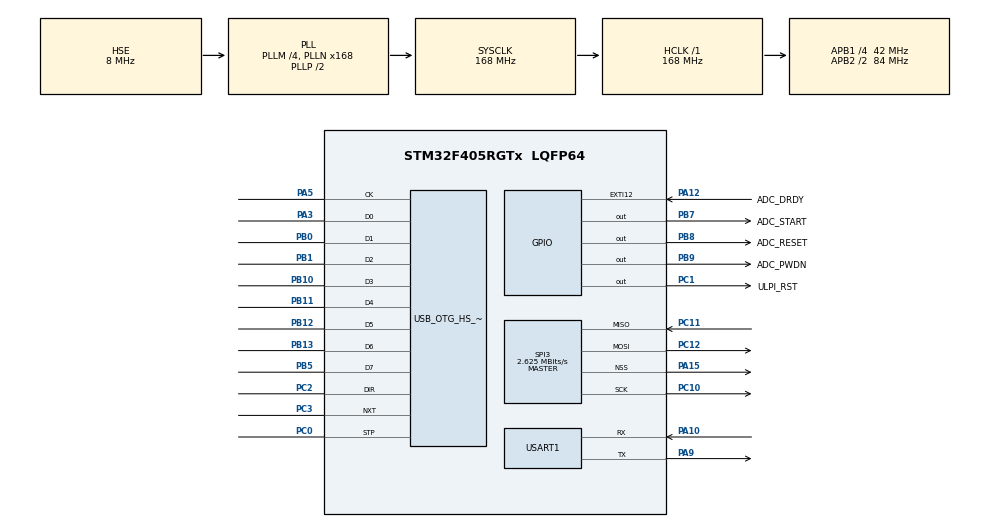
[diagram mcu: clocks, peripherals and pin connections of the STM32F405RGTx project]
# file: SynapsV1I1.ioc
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Dma.Request0=SPI3_RX
Dma.Request1=SPI3_TX
Dma.SPI3_RX.0.Direction=DMA_PERIPH_TO_MEMORY
Dma.SPI3_RX.0.FIFOMode=DMA_FIFOMODE_DISABLE
Dma.SPI3_RX.0.Instance=DMA1_Stream0
Dma.SPI3_RX.0.MemDataAlignment=DMA_MDATAALIGN_BYTE
Dma.SPI3_RX.0.MemInc=DMA_MINC_ENABLE
Dma.SPI3_RX.0.Mode=DMA_NORMAL
Dma.SPI3_RX.0.PeriphDataAlignment=DMA_PDATAALIGN_BYTE
Dma.SPI3_RX.0.PeriphInc=DMA_PINC_DISABLE
Dma.SPI3_RX.0.Priority=DMA_PRIORITY_HIGH
Dma.SPI3_TX.1.Direction=DMA_MEMORY_TO_PERIPH
Dma.SPI3_TX.1.FIFOMode=DMA_FIFOMODE_DISABLE
Dma.SPI3_TX.1.Instance=DMA1_Stream5
Dma.SPI3_TX.1.MemDataAlignment=DMA_MDATAALIGN_BYTE
Dma.SPI3_TX.1.MemInc=DMA_MINC_ENABLE
Dma.SPI3_TX.1.Mode=DMA_NORMAL
Dma.SPI3_TX.1.PeriphDataAlignment=DMA_PDATAALIGN_BYTE
Dma.SPI3_TX.1.PeriphInc=DMA_PINC_DISABLE
Dma.SPI3_TX.1.Priority=DMA_PRIORITY_HIGH
FREERTOS.BinarySemaphores01=adcDataReadySemathore,Dynamic,NULL
FREERTOS.INCLUDE_pcTaskGetTaskName=0
FREERTOS.INCLUDE_uxTaskPriorityGet=0
FREERTOS.INCLUDE_vTaskDelayUntil=1
FREERTOS.INCLUDE_vTaskDelete=0
FREERTOS.INCLUDE_vTaskPrioritySet=0
FREERTOS.Queues01=USB_Tx_Queue,8192,uint8_t,0,Dynamic,NULL,NULL;USB_Rx_Queue,512,uint8_t,0,Dynamic,NULL,NULL;SerialTxQueue,8192,uint8_t,0,Dynamic,NULL,NULL;SerialRxQueue,256,uint8_t,0,Dynamic,NULL,NULL
FREERTOS.Tasks01=defaultTask,0,128,StartDefaultTask,Default,NULL,Dynamic,NULL,NULL;USB,0,1024,usbTaskWorker,As external,NULL,Dynamic,NULL,NULL;OpenBCI,0,1024,OpenBCITaskWorker,As external,NULL,Dynamic,NULL,NULL;CmdProc,0,1024,OpenBCICommandTaskWorker,As external,NULL,Dynamic,NULL,NULL
FREERTOS.configTOTAL_HEAP_SIZE=32768
Mcu.Family=STM32F4
Mcu.Name=STM32F405RGTx
Mcu.Package=LQFP64
NVIC.DMA1_Stream0_IRQn=true\:5\:0\:false\:false\:true\:true\:false
NVIC.DMA1_Stream5_IRQn=true\:5\:0\:false\:false\:true\:true\:false
NVIC.EXTI15_10_IRQn=true\:5\:0\:false\:false\:true\:true\:true
NVIC.OTG_HS_IRQn=true\:5\:0\:false\:false\:true\:true\:false
NVIC.PriorityGroup=NVIC_PRIORITYGROUP_4
NVIC.TIM8_TRG_COM_TIM14_IRQn=true\:0\:0\:false\:false\:true\:false\:false
NVIC.TimeBase=TIM8_TRG_COM_TIM14_IRQn
NVIC.TimeBaseIP=TIM14
NVIC.USART1_IRQn=true\:5\:0\:false\:false\:true\:true\:true
PA10.Mode=Asynchronous
PA10.Signal=USART1_RX
PA12.GPIO_Label=ADC_DRDY
PA12.GPIO_ModeDefaultEXTI=GPIO_MODE_IT_FALLING
PA12.GPIO_PuPd=GPIO_PULLUP
PA12.Signal=GPXTI12
PA13.Mode=Serial_Wire
PA13.Signal=SYS_JTMS-SWDIO
PA14.Mode=Serial_Wire
PA14.Signal=SYS_JTCK-SWCLK
PA15.Mode=NSS_Signal_Hard_Output
PA15.Signal=SPI3_NSS
PA3.Mode=Device_HS
PA3.Signal=USB_OTG_HS_ULPI_D0
PA5.Mode=Device_HS
PA5.Signal=USB_OTG_HS_ULPI_CK
PA9.Mode=Asynchronous
PA9.Signal=USART1_TX
PB0.Mode=Device_HS
PB0.Signal=USB_OTG_HS_ULPI_D1
PB1.Mode=Device_HS
PB1.Signal=USB_OTG_HS_ULPI_D2
PB10.Mode=Device_HS
PB10.Signal=USB_OTG_HS_ULPI_D3
PB11.Mode=Device_HS
PB11.Signal=USB_OTG_HS_ULPI_D4
PB12.Mode=Device_HS
PB12.Signal=USB_OTG_HS_ULPI_D5
PB13.Mode=Device_HS
PB13.Signal=USB_OTG_HS_ULPI_D6
PB5.Mode=Device_HS
PB5.Signal=USB_OTG_HS_ULPI_D7
PB7.GPIO_Label=ADC_START
PB7.Signal=GPIO_Output
PB8.GPIO_Label=ADC_RESET
PB8.GPIO_PuPd=GPIO_NOPULL
PB8.PinState=GPIO_PIN_SET
PB8.Signal=GPIO_Output
PB9.GPIO_Label=ADC_PWDN
PB9.PinState=GPIO_PIN_SET
PB9.Signal=GPIO_Output
PC0.Mode=Device_HS
PC0.Signal=USB_OTG_HS_ULPI_STP
PC1.GPIO_Label=ULPI_RST
PC1.Signal=GPIO_Output
PC10.Mode=Full_Duplex_Master
PC10.Signal=SPI3_SCK
PC11.Mode=Full_Duplex_Master
PC11.Signal=SPI3_MISO
PC12.Mode=Full_Duplex_Master
PC12.Signal=SPI3_MOSI
PC2.Mode=Device_HS
PC2.Signal=USB_OTG_HS_ULPI_DIR
PC3.Mode=Device_HS
PC3.Signal=USB_OTG_HS_ULPI_NXT
PH0-OSC_IN.Mode=HSE-External-Oscillator
PH0-OSC_IN.Signal=RCC_OSC_IN
PH1-OSC_OUT.Mode=HSE-External-Oscillator
PH1-OSC_OUT.Signal=RCC_OSC_OUT
ProjectManager.HeapSize=0x200
ProjectManager.StackSize=0x400
ProjectManager.TargetToolchain=SW4STM32
RCC.48MHZClocksFreq_Value=84000000
RCC.AHBFreq_Value=168000000
RCC.APB1CLKDivider=RCC_HCLK_DIV4
RCC.APB1Freq_Value=42000000
RCC.APB1TimFreq_Value=84000000
RCC.APB2CLKDivider=RCC_HCLK_DIV2
RCC.APB2Freq_Value=84000000
RCC.APB2TimFreq_Value=168000000
RCC.CortexFreq_Value=168000000
RCC.HCLKFreq_Value=168000000
RCC.HSE_VALUE=8000000
RCC.HSI_VALUE=16000000
RCC.LSE_VALUE=32768
RCC.PLLM=4
RCC.PLLN=168
RCC.PLLSourceVirtual=RCC_PLLSOURCE_HSE
RCC.SYSCLKFreq_VALUE=168000000
RCC.SYSCLKSource=RCC_SYSCLKSOURCE_PLLCLK
RCC.VCOOutputFreq_Value=336000000
SPI3.BaudRatePrescaler=SPI_BAUDRATEPRESCALER_16
SPI3.CLKPhase=SPI_PHASE_2EDGE
SPI3.CLKPolarity=SPI_POLARITY_LOW
SPI3.CalculateBaudRate=2.625 MBits/s
SPI3.Direction=SPI_DIRECTION_2LINES
SPI3.Mode=SPI_MODE_MASTER
SPI3.VirtualNSS=VM_NSSHARD
SPI3.VirtualType=VM_MASTER
USART1.VirtualMode=VM_ASYNC
USB_DEVICE.CLASS_NAME_HS=CDC
USB_DEVICE.VirtualMode-CDC_HS=Cdc
USB_DEVICE.VirtualModeHS=Cdc_HS
USB_OTG_HS.VirtualMode-Device_HS=Device_HS
VP_CRC_VS_CRC.Mode=CRC_Activate
VP_FREERTOS_VS_ENABLE.Mode=Enabled
VP_IWDG_VS_IWDG.Mode=IWDG_Activate
VP_SYS_VS_tim14.Mode=TIM14
VP_USB_DEVICE_VS_USB_DEVICE_CDC_HS.Mode=CDC_HS
board=SynapsV1I1

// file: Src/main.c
/* USER CODE BEGIN Header */
/**
  ******************************************************************************
  * @file           : main.c
  * @brief          : Main program body
  ******************************************************************************
  * This notice applies to any and all portions of this file
  * that are not between comment pairs USER CODE BEGIN and
  * USER CODE END. Other portions of this file, whether
  * inserted by the user or by software development tools
  * are owned by their respective copyright owners.
  *
  * Copyright (c) 2018 STMicroelectronics International N.V.
  * All rights reserved.
  *
  * Redistribution and use in source and binary forms, with or without
  * modification, are permitted, provided that the following conditions are met:
  *
  * 1. Redistribution of source code must retain the above copyright notice,
  *    this list of conditions and the following disclaimer.
  * 2. Redistributions in binary form must reproduce the above copyright notice,
  *    this list of conditions and the following disclaimer in the documentation
  *    and/or other materials provided with the distribution.
  * 3. Neither the name of STMicroelectronics nor the names of other
  *    contributors to this software may be used to endorse or promote products
  *    derived from this software without specific written permission.
  * 4. This software, including modifications and/or derivative works of this
  *    software, must execute solely and exclusively on microcontroller or
  *    microprocessor devices manufactured by or for STMicroelectronics.
  * 5. Redistribution and use of this software other than as permitted under
  *    this license is void and will automatically terminate your rights under
  *    this license.
  *
  * THIS SOFTWARE IS PROVIDED BY STMICROELECTRONICS AND CONTRIBUTORS "AS IS"
  * AND ANY EXPRESS, IMPLIED OR STATUTORY WARRANTIES, INCLUDING, BUT NOT
  * LIMITED TO, THE IMPLIED WARRANTIES OF MERCHANTABILITY, FITNESS FOR A
  * PARTICULAR PURPOSE AND NON-INFRINGEMENT OF THIRD PARTY INTELLECTUAL PROPERTY
  * RIGHTS ARE DISCLAIMED TO THE FULLEST EXTENT PERMITTED BY LAW. IN NO EVENT
  * SHALL STMICROELECTRONICS OR CONTRIBUTORS BE LIABLE FOR ANY DIRECT, INDIRECT,
  * INCIDENTAL, SPECIAL, EXEMPLARY, OR CONSEQUENTIAL DAMAGES (INCLUDING, BUT NOT
  * LIMITED TO, PROCUREMENT OF SUBSTITUTE GOODS OR SERVICES; LOSS OF USE, DATA,
  * OR PROFITS; OR BUSINESS INTERRUPTION) HOWEVER CAUSED AND ON ANY THEORY OF
  * LIABILITY, WHETHER IN CONTRACT, STRICT LIABILITY, OR TORT (INCLUDING
  * NEGLIGENCE OR OTHERWISE) ARISING IN ANY WAY OUT OF THE USE OF THIS SOFTWARE,
  * EVEN IF ADVISED OF THE POSSIBILITY OF SUCH DAMAGE.
  *
  ******************************************************************************
  */
/* USER CODE END Header */

#include "main.h"
#include "cmsis_os.h"
#include "crc.h"
#include "dma.h"
#include "iwdg.h"
#include "spi.h"
#include "usart.h"
#include "usb_device.h"
#include "gpio.h"

/* USER CODE BEGIN PV */
/* Private variables ---------------------------------------------------------*/

/* USER CODE END PV */

void SystemClock_Config(void);
void MX_FREERTOS_Init(void);
/* USER CODE BEGIN PFP */
/* Private function prototypes -----------------------------------------------*/

/* USER CODE END PFP */

int main(void)
{

  /* MCU Configuration--------------------------------------------------------*/

  /* Reset of all peripherals, Initializes the Flash interface and the Systick. */
  HAL_Init();

  /* Configure the system clock */
  SystemClock_Config();

  /* Initialize all configured peripherals */
  MX_GPIO_Init();
  MX_DMA_Init();
  MX_CRC_Init();
  MX_IWDG_Init();
  MX_SPI3_Init();
  MX_USART1_UART_Init();

  /* Call init function for freertos objects (in freertos.c) */
  MX_FREERTOS_Init();

  /* Start scheduler */
  osKernelStart();

  /* We should never get here as control is now taken by the scheduler */

  /* Infinite loop */
  while (1)
  {

  }
}

void SystemClock_Config(void)
{
  RCC_OscInitTypeDef RCC_OscInitStruct = {0};
  RCC_ClkInitTypeDef RCC_ClkInitStruct = {0};

  /**Configure the main internal regulator output voltage
  */
  __HAL_RCC_PWR_CLK_ENABLE();
  __HAL_PWR_VOLTAGESCALING_CONFIG(PWR_REGULATOR_VOLTAGE_SCALE1);
  /**Initializes the CPU, AHB and APB busses clocks
  */
  RCC_OscInitStruct.OscillatorType = RCC_OSCILLATORTYPE_LSI|RCC_OSCILLATORTYPE_HSE;
  RCC_OscInitStruct.HSEState = RCC_HSE_ON;
  RCC_OscInitStruct.LSIState = RCC_LSI_ON;
  RCC_OscInitStruct.PLL.PLLState = RCC_PLL_ON;
  RCC_OscInitStruct.PLL.PLLSource = RCC_PLLSOURCE_HSE;
  RCC_OscInitStruct.PLL.PLLM = 4;
  RCC_OscInitStruct.PLL.PLLN = 168;
  RCC_OscInitStruct.PLL.PLLP = RCC_PLLP_DIV2;
  RCC_OscInitStruct.PLL.PLLQ = 4;
  if (HAL_RCC_OscConfig(&RCC_OscInitStruct) != HAL_OK)
  {
    Error_Handler();
  }
  /**Initializes the CPU, AHB and APB busses clocks
  */
  RCC_ClkInitStruct.ClockType = RCC_CLOCKTYPE_HCLK|RCC_CLOCKTYPE_SYSCLK
                              |RCC_CLOCKTYPE_PCLK1|RCC_CLOCKTYPE_PCLK2;
  RCC_ClkInitStruct.SYSCLKSource = RCC_SYSCLKSOURCE_PLLCLK;
  RCC_ClkInitStruct.AHBCLKDivider = RCC_SYSCLK_DIV1;
  RCC_ClkInitStruct.APB1CLKDivider = RCC_HCLK_DIV4;
  RCC_ClkInitStruct.APB2CLKDivider = RCC_HCLK_DIV2;

  if (HAL_RCC_ClockConfig(&RCC_ClkInitStruct, FLASH_LATENCY_5) != HAL_OK)
  {
    Error_Handler();
  }
}

void HAL_TIM_PeriodElapsedCallback(TIM_HandleTypeDef *htim)
{
  if (htim->Instance == TIM14) {
    HAL_IncTick();
  }
}

void Error_Handler(void)
{
  while(1)
  {
  }
}

/************************ (C) COPYRIGHT STMicroelectronics *****END OF FILE****/

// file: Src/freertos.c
/* USER CODE BEGIN Header */
/**
  ******************************************************************************
  * File Name          : freertos.c
  * Description        : Code for freertos applications
  ******************************************************************************
  * This notice applies to any and all portions of this file
  * that are not between comment pairs USER CODE BEGIN and
  * USER CODE END. Other portions of this file, whether
  * inserted by the user or by software development tools
  * are owned by their respective copyright owners.
  *
  * Copyright (c) 2018 STMicroelectronics International N.V.
  * All rights reserved.
  *
  * Redistribution and use in source and binary forms, with or without
  * modification, are permitted, provided that the following conditions are met:
  *
  * 1. Redistribution of source code must retain the above copyright notice,
  *    this list of conditions and the following disclaimer.
  * 2. Redistributions in binary form must reproduce the above copyright notice,
  *    this list of conditions and the following disclaimer in the documentation
  *    and/or other materials provided with the distribution.
  * 3. Neither the name of STMicroelectronics nor the names of other
  *    contributors to this software may be used to endorse or promote products
  *    derived from this software without specific written permission.
  * 4. This software, including modifications and/or derivative works of this
  *    software, must execute solely and exclusively on microcontroller or
  *    microprocessor devices manufactured by or for STMicroelectronics.
  * 5. Redistribution and use of this software other than as permitted under
  *    this license is void and will automatically terminate your rights under
  *    this license.
  *
  * THIS SOFTWARE IS PROVIDED BY STMICROELECTRONICS AND CONTRIBUTORS "AS IS"
  * AND ANY EXPRESS, IMPLIED OR STATUTORY WARRANTIES, INCLUDING, BUT NOT
  * LIMITED TO, THE IMPLIED WARRANTIES OF MERCHANTABILITY, FITNESS FOR A
  * PARTICULAR PURPOSE AND NON-INFRINGEMENT OF THIRD PARTY INTELLECTUAL PROPERTY
  * RIGHTS ARE DISCLAIMED TO THE FULLEST EXTENT PERMITTED BY LAW. IN NO EVENT
  * SHALL STMICROELECTRONICS OR CONTRIBUTORS BE LIABLE FOR ANY DIRECT, INDIRECT,
  * INCIDENTAL, SPECIAL, EXEMPLARY, OR CONSEQUENTIAL DAMAGES (INCLUDING, BUT NOT
  * LIMITED TO, PROCUREMENT OF SUBSTITUTE GOODS OR SERVICES; LOSS OF USE, DATA,
  * OR PROFITS; OR BUSINESS INTERRUPTION) HOWEVER CAUSED AND ON ANY THEORY OF
  * LIABILITY, WHETHER IN CONTRACT, STRICT LIABILITY, OR TORT (INCLUDING
  * NEGLIGENCE OR OTHERWISE) ARISING IN ANY WAY OUT OF THE USE OF THIS SOFTWARE,
  * EVEN IF ADVISED OF THE POSSIBILITY OF SUCH DAMAGE.
  *
  ******************************************************************************
  */
/* USER CODE END Header */

#include "FreeRTOS.h"
#include "task.h"
#include "main.h"
#include "cmsis_os.h"

/* USER CODE BEGIN Includes */
#include "iwdg.h"

/* USER CODE END Includes */

osThreadId defaultTaskHandle;
osThreadId USBHandle;
osThreadId OpenBCIHandle;
osThreadId CmdProcHandle;
osMessageQId USB_Tx_QueueHandle;
osMessageQId USB_Rx_QueueHandle;
osMessageQId SerialTxQueueHandle;
osMessageQId SerialRxQueueHandle;
osSemaphoreId adcDataReadySemathoreHandle;

void StartDefaultTask(void const * argument);
extern void usbTaskWorker(void const * argument);
extern void OpenBCITaskWorker(void const * argument);
extern void OpenBCICommandTaskWorker(void const * argument);

extern void MX_USB_DEVICE_Init(void);
void MX_FREERTOS_Init(void); /* (MISRA C 2004 rule 8.1) */

void MX_FREERTOS_Init(void) {

  /* Create the semaphores(s) */
  /* definition and creation of adcDataReadySemathore */
  osSemaphoreDef(adcDataReadySemathore);
  adcDataReadySemathoreHandle = osSemaphoreCreate(osSemaphore(adcDataReadySemathore), 1);

  /* Create the thread(s) */
  /* definition and creation of defaultTask */
  osThreadDef(defaultTask, StartDefaultTask, osPriorityNormal, 0, 128);
  defaultTaskHandle = osThreadCreate(osThread(defaultTask), NULL);

  /* definition and creation of USB */
  osThreadDef(USB, usbTaskWorker, osPriorityNormal, 0, 1024);
  USBHandle = osThreadCreate(osThread(USB), NULL);

  /* definition and creation of OpenBCI */
  osThreadDef(OpenBCI, OpenBCITaskWorker, osPriorityNormal, 0, 1024);
  OpenBCIHandle = osThreadCreate(osThread(OpenBCI), NULL);

  /* definition and creation of CmdProc */
  osThreadDef(CmdProc, OpenBCICommandTaskWorker, osPriorityNormal, 0, 1024);
  CmdProcHandle = osThreadCreate(osThread(CmdProc), NULL);

  /* Create the queue(s) */
  /* definition and creation of USB_Tx_Queue */
  osMessageQDef(USB_Tx_Queue, 8192, uint8_t);
  USB_Tx_QueueHandle = osMessageCreate(osMessageQ(USB_Tx_Queue), NULL);

  /* definition and creation of USB_Rx_Queue */
  osMessageQDef(USB_Rx_Queue, 512, uint8_t);
  USB_Rx_QueueHandle = osMessageCreate(osMessageQ(USB_Rx_Queue), NULL);

  /* definition and creation of SerialTxQueue */
  osMessageQDef(SerialTxQueue, 8192, uint8_t);
  SerialTxQueueHandle = osMessageCreate(osMessageQ(SerialTxQueue), NULL);

  /* definition and creation of SerialRxQueue */
  osMessageQDef(SerialRxQueue, 256, uint8_t);
  SerialRxQueueHandle = osMessageCreate(osMessageQ(SerialRxQueue), NULL);

}

void StartDefaultTask(void const * argument)
{
  /* init code for USB_DEVICE */
  MX_USB_DEVICE_Init();

  /* USER CODE BEGIN StartDefaultTask */

  /* Infinite loop */
  for(;;)
  {
      syIwdgRefresh();

      osDelay(200);
  }
  /* USER CODE END StartDefaultTask */
}

/************************ (C) COPYRIGHT STMicroelectronics *****END OF FILE****/
